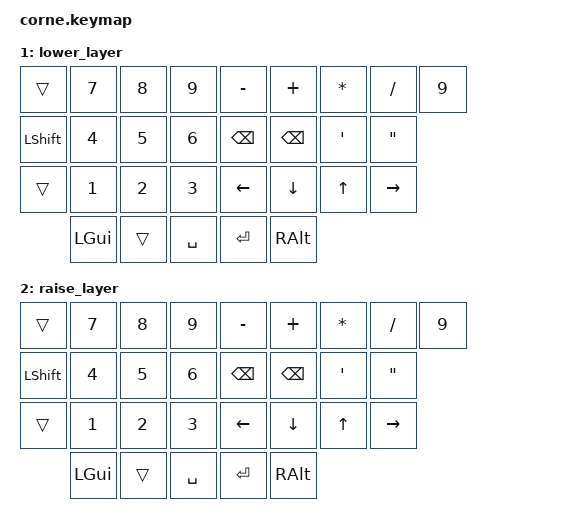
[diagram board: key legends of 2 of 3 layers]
/*
 * Copyright (c) 2020 The ZMK Contributors
 *
 * SPDX-License-Identifier: MIT
 */

#include <behaviors.dtsi>
#include <dt-bindings/zmk/keys.h>
#include <dt-bindings/zmk/bt.h>

/ {
        keymap {
                compatible = "zmk,keymap";

                default_layer {
// -----------------------------------------------------------------------------------------
// |  TAB |  Q  |  W  |  E  |  R  |  T  |   |  Y  |  U   |  I  |  O  |  P  | BSPC |
// | CTRL |  A  |  S  |  D  |  F  |  G  |   |  H  |  J   |  K  |  L  |  ;  |  '   |
// | SHFT |  Z  |  X  |  C  |  V  |  B  |   |  N  |  M   |  ,  |  .  |  /  | ESC  |
//                    | GUI | LWR | SPC |   | ENT | RSE  | ALT |
//                        bindings = <
//   &kp TAB   &kp Q &kp W &kp E &kp R &kp T   &kp Y &kp U  &kp I     &kp O   &kp P    &kp BSPC
//   &kp LCTRL &kp A &kp S &kp D &kp F &kp G   &kp H &kp J  &kp K     &kp L   &kp SEMI &kp SQT
//   &kp LSHFT &kp Z &kp X &kp C &kp V &kp B   &kp N &kp M  &kp COMMA &kp DOT &kp FSLH &kp ESC
//                  &kp LGUI &mo 1 &kp SPACE   &kp RET &mo 2 &kp RALT
//                        >;

// -----------------------------------------------------------------------------------------
// |  d  |  w  |  f  |  p  |   |  m  |  u   |  y  |  ;  |
// |  a  |  r  |  s  |  t  |   |  n  |  e   |  i  |  o  |
// |  g  |  X  |  C  |  V  |   |  h  |  j   |  k  |  l  |
//       | GUI | LWR | SPC |   | ENT | RSE  | ALT |
                  bindings = <
   &kp d &kp w    &kp f &kp p        &kp m   &kp u &kp y &kp SEMI
   &kp a &kp r    &kp s &kp t        &kp n   &kp e &kp i &kp o
   &kp g &kp x    &kp c &kp v        &kp h   &kp j &kp k &kp l
         &kp LGUI &mo 1 &kp SPACE    &kp RET &mo 2
                  >;
                };
                lower_layer {
// -----------------------------------------------------------------------------------------
// |  TAB |  1  |  2  |  3  |  4  |  5  |   |  6  |  7  |  8  |  9  |  0  | BSPC |
// | BTCLR| BT1 | BT2 | BT3 | BT4 | BT5 |   | LFT | DWN |  UP | RGT |     |      |
// | SHFT |     |     |     |     |     |   |     |     |     |     |     |      |
//                    | GUI |     | SPC |   | ENT |     | ALT |
//                        bindings = <
//   &kp TAB    &kp N1       &kp N2       &kp N3       &kp N4       &kp N5         &kp N6   &kp N7   &kp N8 &kp N9    &kp N0 &kp BSPC
//   &bt BT_CLR &bt BT_SEL 0 &bt BT_SEL 1 &bt BT_SEL 2 &bt BT_SEL 3 &bt BT_SEL 4   &kp LEFT &kp DOWN &kp UP &kp RIGHT &trans &trans
//   &kp LSHFT  &trans       &trans       &trans       &trans       &trans         &trans   &trans   &trans &trans    &trans &trans
//                                    &kp LGUI     &trans       &kp SPACE      &kp RET  &trans   &kp RALT
//                        >;

// -----------------------------------------------------------------------------------------
// |     |  7  |  8  |  9  |   |  -  |  +  |  *  |  /  |
// | SHFT|  4  |  5  |  6  |   | BSPC| DEL |  '  |  "  |
// |     |  1  |  2  |  3  |   | LFT | DWN |  UP | RGT |
//       | GUI |     | SPC |   | ENT |     | ALT |
                        bindings = <
   &trans    &kp N7   &kp N8 &kp N9       &kp MINUS  &kp PLUS &kp ASTRK &kp FSLH &kp N9
   &kp LSHFT &kp N4   &kp N5 &kp N6       &kp BSPC   &kp BSPC &kp SQT   &kp DQT
   &trans    &kp N1   &kp N2 &kp N3       &kp LEFT   &kp DOWN &kp UP    &kp RIGHT
             &kp LGUI &trans &kp SPACE    &kp RET    &kp RALT
                        >;
                };

                raise_layer {
// -----------------------------------------------------------------------------------------
// |  TAB |  !  |  @  |  #  |  $  |  %  |   |  ^  |  &  |  *  |  (  |  )  | BSPC |
// | CTRL |     |     |     |     |     |   |  -  |  =  |  [  |  ]  |  \  |  `   |
// | SHFT |     |     |     |     |     |   |  _  |  +  |  {  |  }  | "|" |  ~   |
//                    | GUI |     | SPC |   | ENT |     | ALT |
//                        bindings = <
//   &kp  TAB  &kp EXCL &kp AT &kp HASH &kp DLLR &kp PRCNT   &kp CARET &kp AMPS  &kp ASTRK &kp LPAR &kp RPAR &kp BSPC
//   &kp LCTRL &trans   &trans &trans   &trans   &trans      &kp MINUS &kp EQUAL &kp LBKT  &kp RBKT &kp BSLH &kp GRAVE
//   &kp LSHFT &trans   &trans &trans   &trans   &trans      &kp UNDER &kp PLUS  &kp LBRC  &kp RBRC &kp PIPE &kp TILDE
//                             &kp LGUI &trans   &kp SPACE   &kp RET   &trans    &kp RALT
//                        >;

// -----------------------------------------------------------------------------------------
// |     |  7  |  8  |  9  |   |  -  |  +  |  *  |  /  |
// | SHFT|  4  |  5  |  6  |   | BSPC| DEL |  '  |  "  |
// |     |  1  |  2  |  3  |   | LFT | DWN |  UP | RGT |
//       | GUI |     | SPC |   | ENT |     | ALT |
                        bindings = <
   &trans    &kp N7   &kp N8 &kp N9       &kp MINUS  &kp PLUS &kp ASTRK &kp FSLH &kp N9
   &kp LSHFT &kp N4   &kp N5 &kp N6       &kp BSPC   &kp BSPC &kp SQT   &kp DQT
   &trans    &kp N1   &kp N2 &kp N3       &kp LEFT   &kp DOWN &kp UP    &kp RIGHT
             &kp LGUI &trans &kp SPACE    &kp RET    &kp RALT
                        >;
                };
        };
};
